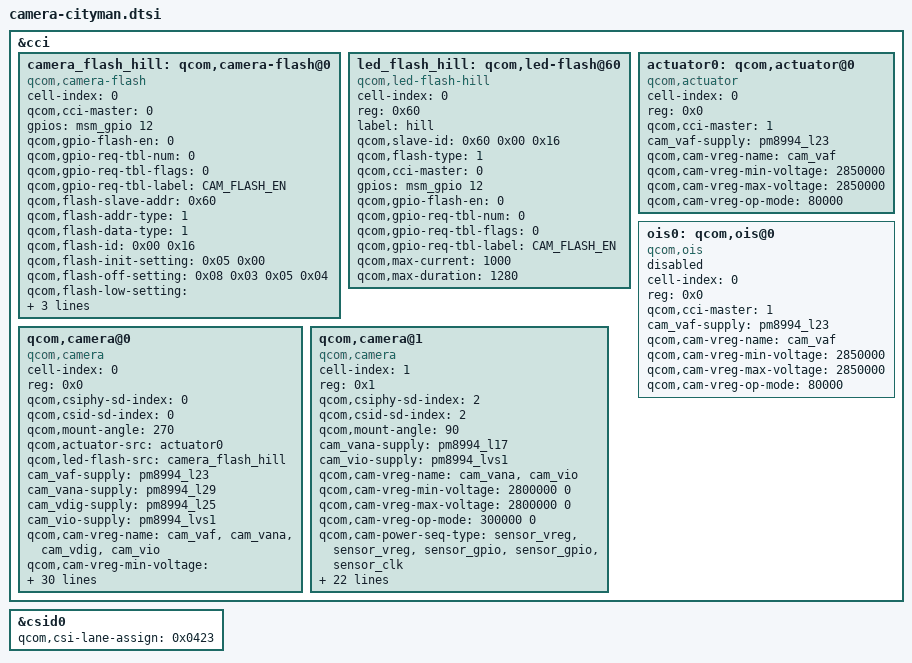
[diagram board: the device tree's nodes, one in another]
/*
 * Lumia 950 XL (cityman) camera sensors.
 *
 * Replaces qcom/msm8994-camera-sensor-mtp.dtsi. The MTP nodes describe
 * IMX214/OV4688 boards: their rails (L27/L17/L3), the rear2 slot on
 * GPIO 94/93 (93 is the SiLabs FM reset here) and the EEPROM addresses do
 * not match this phone.
 *
 * Wiring comes from the Lumia ACPI tables (DSDT CAMS/CAMF devices) and was
 * confirmed on the phone with CCI reads:
 *
 *   rear  - Carrera module, Sony IMX230 die (0x0016 = 0x0230)
 *           CCI master 1, slave 0x20, CSIPHY0/CSID0, MCLK0
 *           reset GPIO 92, standby GPIO 91
 *           VAF L23 2.85 V, VANA L29 2.85 V, VDIG L25 1.15 V, VIO LVS1
 *   front - Ducati module, die ID 0x03bb at 0x0016 (part number unconfirmed)
 *           CCI master 0, slave 0x20, CSIPHY2/CSID2, MCLK2
 *           reset GPIO 104, standby GPIO 105
 *           VANA L17 2.8 V, VIO LVS1
 *
 * The front sensor keeps cell-index 1 because the camera HAL expects slot 1
 * for the front camera; only the PHY/CSID indexes point at CSI2.
 *
 * Both sensors use a 9.6 MHz MCLK (DSDT). The power sequence actually used
 * at probe time is sent by the userspace sensor library; the sequence below
 * documents the order and is used by the legacy/EEPROM paths.
 *
 * EEPROM nodes are left out: their CCI addresses on the Lumia modules are
 * not known yet.
 */

/*
 * Rear flash.
 *
 * The rear LEDs are not on PMI8994.  The DSDT has two flash devices:
 *
 *   FLSH  QCOM244B  _DEP CAMF, CAMS  no resources at all
 *   FLHT  QCOM244C  _DEP CAMT, FLSH  PM02 interrupts 0xe9e/0xe9f
 *
 * 0xe9e/0xe9f are bits 6/7 of PMIC peripheral 0x1d3, i.e. PMI8994's flash
 * block at 0xd300, and FLHT is the "tertiary" flash that follows CAMT, the
 * iris camera.  The rear flash, FLSH, has no PMIC resource and is driven by
 * qccamflash8994.sys over the camera platform's CCI, the same arrangement
 * as the Lumia 950 (talkman): Nokia's WhiteLEDFlashDriver, which probes
 * register 0 at 8-bit 0x60 and expects 0x16 for the "Hill" three-channel
 * driver.  That is why the qcom,camera-flash node copied from the MTP
 * (qcom,flash-source = <&pmi8994_flash0 &pmi8994_flash1>) lit nothing at
 * the back: led:torch_0/1 most likely drive the iris illuminator.
 *
 * Hill's address, CCI master and register map are taken from the Lumia 950,
 * where they were measured on the hardware; both nodes below read the ID
 * register before the first write, so a different part is reported in
 * dmesg instead of being driven.  GPIO 12 is in the CAMP resource list here
 * as on the 950, where it is the flash pin of the schematic; Hill lights
 * with it low.
 */

&cci {
	/*
	 * Hill through msm_flash.c (subdev group 16), the only flash the
	 * camera daemon can see.  The daemon takes the address, power
	 * sequence and register arrays from libflash_hill.so; the properties
	 * below are the fallback for the HAL torch (QCameraFlash), which opens
	 * this subdev directly and sends no register settings.
	 *
	 *   0x02/0x03/0x04  LED1/2/3 current, torch level in bits [7:5]
	 *   0x05            mode: 0x00 power on, 0x04 power off, 0x19 normal
	 *   0x06            VPH_PWR droop compensation
	 *   0x07            safety timer code
	 *   0x08            enable: 0x03 standby, 0x06 torch, 0x07 flash
	 *
	 * Torch level 4 (0x80) for low, level 7 (0xe0) in torch mode for high:
	 * msm_flash.c switches a high setting off after flash_high_timeout_ms.
	 */
	camera_flash_hill: qcom,camera-flash@0 {
		cell-index = <0>;
		compatible = "qcom,camera-flash";
		qcom,cci-master = <0>;
		gpios = <&msm_gpio 12 0>;
		qcom,gpio-flash-en = <0>;
		qcom,gpio-req-tbl-num = <0>;
		qcom,gpio-req-tbl-flags = <0>;
		qcom,gpio-req-tbl-label = "CAM_FLASH_EN";
		qcom,flash-slave-addr = <0x60>;
		qcom,flash-addr-type = <1>;	/* MSM_CAMERA_I2C_BYTE_ADDR */
		qcom,flash-data-type = <1>;	/* MSM_CAMERA_I2C_BYTE_DATA */
		qcom,flash-id = <0x00 0x16>;
		qcom,flash-init-setting = /bits/ 16 <0x05 0x00>;
		qcom,flash-off-setting  = /bits/ 16 <0x08 0x03
						     0x05 0x04>;
		qcom,flash-low-setting  = /bits/ 16 <0x02 0x80
						     0x03 0x80
						     0x04 0x80
						     0x05 0x19
						     0x06 0x00
						     0x07 0x00
						     0x08 0x06>;
		qcom,flash-high-setting = /bits/ 16 <0x02 0xe0
						     0x03 0xe0
						     0x04 0xe0
						     0x05 0x19
						     0x06 0x00
						     0x07 0x00
						     0x08 0x06>;
		status = "ok";
	};

	/*
	 * The same part through the older msm_led_flash framework (hill.c),
	 * for /sys/class/leds/flash-torch: a flashlight that needs no camera
	 * stack, and a way to check the hardware with the kernel alone.
	 * Its group (11) is invisible to the daemon.  Do not use it while a
	 * camera session holds GPIO 12.
	 */
	led_flash_hill: qcom,led-flash@60 {
		cell-index = <0>;
		reg = <0x60>;
		compatible = "qcom,led-flash-hill";
		label = "hill";
		qcom,slave-id = <0x60 0x00 0x16>;
		qcom,flash-type = <1>;
		qcom,cci-master = <0>;
		gpios = <&msm_gpio 12 0>;
		qcom,gpio-flash-en = <0>;
		qcom,gpio-req-tbl-num = <0>;
		qcom,gpio-req-tbl-flags = <0>;
		qcom,gpio-req-tbl-label = "CAM_FLASH_EN";
		qcom,max-current = <1000>;
		qcom,max-duration = <1280>;
		status = "ok";
	};

	/*
	 * AF and OIS live in one controller inside the rear Carrera module,
	 * on the rear sensor's CCI master. The Windows SMIA++ driver talks to
	 * it at 8-bit address 0x7c with 16-bit register addresses (lens
	 * position 0x05f0, OIS control 0x0520). msm_actuator takes the slave
	 * address from the userspace actuator library, not from this node.
	 *
	 * OIS stays disabled: its mode sequences are known but the
	 * calibration upload from the module NVM is not implemented.
	 */
	actuator0: qcom,actuator@0 {
		cell-index = <0>;
		reg = <0x0>;
		compatible = "qcom,actuator";
		qcom,cci-master = <1>;
		cam_vaf-supply = <&pm8994_l23>;
		qcom,cam-vreg-name = "cam_vaf";
		qcom,cam-vreg-min-voltage = <2850000>;
		qcom,cam-vreg-max-voltage = <2850000>;
		qcom,cam-vreg-op-mode = <80000>;
	};

	ois0: qcom,ois@0 {
		cell-index = <0>;
		status = "disabled";
		reg = <0x0>;
		compatible = "qcom,ois";
		qcom,cci-master = <1>;
		cam_vaf-supply = <&pm8994_l23>;
		qcom,cam-vreg-name = "cam_vaf";
		qcom,cam-vreg-min-voltage = <2850000>;
		qcom,cam-vreg-max-voltage = <2850000>;
		qcom,cam-vreg-op-mode = <80000>;
	};

	/* Rear: Carrera / IMX230 */
	qcom,camera@0 {
		cell-index = <0>;
		compatible = "qcom,camera";
		reg = <0x0>;
		qcom,csiphy-sd-index = <0>;
		qcom,csid-sd-index = <0>;
		qcom,mount-angle = <270>;
		qcom,actuator-src = <&actuator0>;
		qcom,led-flash-src = <&camera_flash_hill>;
		cam_vaf-supply = <&pm8994_l23>;
		cam_vana-supply = <&pm8994_l29>;
		cam_vdig-supply = <&pm8994_l25>;
		cam_vio-supply = <&pm8994_lvs1>;
		qcom,cam-vreg-name = "cam_vaf", "cam_vana", "cam_vdig", "cam_vio";
		qcom,cam-vreg-min-voltage = <2850000 2850000 1150000 0>;
		qcom,cam-vreg-max-voltage = <2850000 2850000 1150000 0>;
		qcom,cam-vreg-op-mode = <80000 80000 80000 0>;
		qcom,cam-power-seq-type = "sensor_vreg", "sensor_vreg",
					  "sensor_vreg", "sensor_vreg",
					  "sensor_gpio", "sensor_gpio",
					  "sensor_clk";
		qcom,cam-power-seq-val = "cam_vaf", "cam_vana", "cam_vdig",
					 "cam_vio", "sensor_gpio_reset",
					 "sensor_gpio_standby",
					 "sensor_cam_mclk";
		qcom,cam-power-seq-cfg-val = <1 1 1 1 1 1 9600000>;
		qcom,cam-power-seq-delay = <1 1 1 1 30 30 5>;
		qcom,gpio-no-mux = <0>;
		pinctrl-names = "cam_default", "cam_suspend";
		pinctrl-0 = <&cam_sensor_mclk0_active &cam_sensor_rear_active>;
		pinctrl-1 = <&cam_sensor_mclk0_suspend &cam_sensor_rear_suspend>;
		gpios = <&msm_gpio 13 0>,
			<&msm_gpio 92 0>,
			<&msm_gpio 91 0>;
		qcom,gpio-reset = <1>;
		qcom,gpio-standby = <2>;
		qcom,gpio-req-tbl-num = <0 1 2>;
		qcom,gpio-req-tbl-flags = <1 0 0>;
		qcom,gpio-req-tbl-label = "CAMIF_MCLK0",
					  "CAM_RESET0",
					  "CAM_STANDBY0";
		qcom,sensor-position = <0>;
		qcom,sensor-mode = <0>;
		qcom,cci-master = <1>;
		status = "ok";
		clocks = <&clock_mmss clk_mclk0_clk_src>,
			 <&clock_mmss clk_camss_mclk0_clk>;
		clock-names = "cam_src_clk", "cam_clk";
	};

	/* Front: Ducati, wired to CSI2; no validated sensor library yet. */
	qcom,camera@1 {
		cell-index = <1>;
		compatible = "qcom,camera";
		reg = <0x1>;
		qcom,csiphy-sd-index = <2>;
		qcom,csid-sd-index = <2>;
		qcom,mount-angle = <90>;
		cam_vana-supply = <&pm8994_l17>;
		cam_vio-supply = <&pm8994_lvs1>;
		qcom,cam-vreg-name = "cam_vana", "cam_vio";
		qcom,cam-vreg-min-voltage = <2800000 0>;
		qcom,cam-vreg-max-voltage = <2800000 0>;
		qcom,cam-vreg-op-mode = <300000 0>;
		qcom,cam-power-seq-type = "sensor_vreg", "sensor_vreg",
					  "sensor_gpio", "sensor_gpio",
					  "sensor_clk";
		qcom,cam-power-seq-val = "cam_vana", "cam_vio",
					 "sensor_gpio_reset",
					 "sensor_gpio_standby",
					 "sensor_cam_mclk";
		qcom,cam-power-seq-cfg-val = <1 1 1 1 9600000>;
		qcom,cam-power-seq-delay = <1 1 30 30 5>;
		qcom,gpio-no-mux = <0>;
		pinctrl-names = "cam_default", "cam_suspend";
		pinctrl-0 = <&cam_sensor_mclk2_active &cam_sensor_front_active>;
		pinctrl-1 = <&cam_sensor_mclk2_suspend &cam_sensor_front_suspend>;
		gpios = <&msm_gpio 15 0>,
			<&msm_gpio 104 0>,
			<&msm_gpio 105 0>;
		qcom,gpio-reset = <1>;
		qcom,gpio-standby = <2>;
		qcom,gpio-req-tbl-num = <0 1 2>;
		qcom,gpio-req-tbl-flags = <1 0 0>;
		qcom,gpio-req-tbl-label = "CAMIF_MCLK2",
					  "CAM_RESET_FRONT",
					  "CAM_STANDBY_FRONT";
		qcom,sensor-position = <1>;
		qcom,sensor-mode = <0>;
		qcom,cci-master = <0>;
		status = "ok";
		clocks = <&clock_mmss clk_mclk2_clk_src>,
			 <&clock_mmss clk_camss_mclk2_clk>;
		clock-names = "cam_src_clk", "cam_clk";
	};
};

/*
 * The rear module's data lanes DL0..DL3 reach CSI0 lanes 2/1/3/0
 * (lane assignment 0x0423), not the 0x4320 order of reference IMX230
 * libraries; with 0x4320 the CSID only sees ECC errors and no frame
 * reaches the VFE. Measured on the Lumia 950 rear module (same module
 * header 0xEACA) by archienz/android_device_msft_talkman.
 */
&csid0 {
	qcom,csi-lane-assign = <0x0423>;
};
